VERSION "HIPBNYYYYYYYYYYYYYYYYYYYYYYYYYYYNNNNNNNNNN/4/%%%/4/'%**4NNN///"

NS_ :

BS_:

BU_: Response CyclicSending

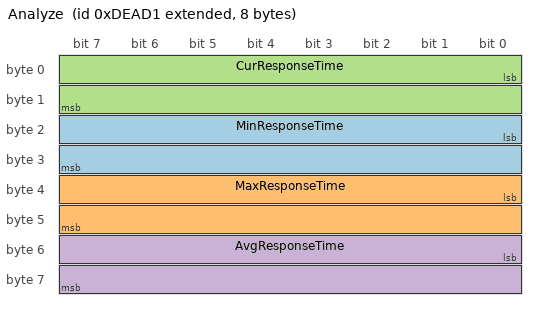
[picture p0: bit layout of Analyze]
BO_ 2148395729 Analyze: 8 Vector__XXX
 SG_ MinResponseTime : 16|16@1- (0.01,0) [-327.68|327.67] "ms" Vector__XXX
 SG_ MaxResponseTime : 32|16@1- (0.01,0) [-327.68|327.67] "ms" Vector__XXX
 SG_ CurResponseTime : 0|16@1- (0.01,0) [-327.68|327.67] "ms" Vector__XXX
 SG_ AvgResponseTime : 48|16@1- (0.01,0) [-327.68|327.67] "ms" Vector__XXX

BO_ 256 CyclicMessage: 4 CyclicSending
 SG_ SendCount : 0|32@1- (1,0) [-2147483648|2147483647] ""  Response

BO_ 258 ResponseMessage: 4 Response
 SG_ ResponseCount : 0|32@1- (1,0) [-2147483648|2147483647] "" Vector__XXX
